# ATSAMA5D26 register map
Vendor: Microchip Technology; Series: SAMA5D2; File version: 0
Registers are 32-bit, read-write, reset 0x0 unless marked. A register's access mark holds for its fields unless they carry their own. Offsets are from the block's base; [hi:lo] are bit positions; 'fields as' and 'values as' point back to an identical list.

## PDMIC — Pulse Density Modulation Interface Controller
Base 0xF8018000
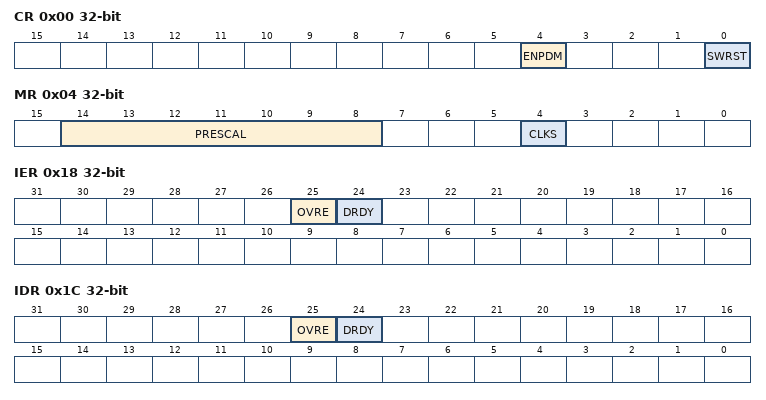
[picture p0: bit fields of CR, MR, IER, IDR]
0x00 CR — Control Register
  [4] ENPDM — Enable PDM
  [0] SWRST — Software Reset
0x04 MR — Mode Register
  [14:8] PRESCAL — Prescaler Rate Selection
  [4] CLKS — Clock Source Selection
0x14 CDR ro — Converted Data Register
  [31:0] DATA — Data Converted
0x18 IER wo — Interrupt Enable Register
  [25] OVRE — Overrun Error Interrupt Enable
  [24] DRDY — Data Ready Interrupt Enable
0x1C IDR wo — Interrupt Disable Register
  [25] OVRE — General Overrun Error Interrupt Disable
  [24] DRDY — Data Ready Interrupt Disable
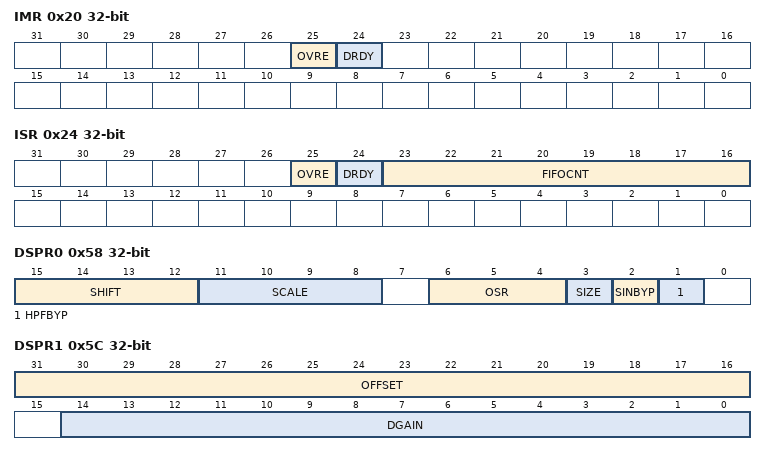
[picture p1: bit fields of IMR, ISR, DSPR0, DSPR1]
0x20 IMR ro — Interrupt Mask Register
  [25] OVRE — General Overrun Error Interrupt Mask
  [24] DRDY — Data Ready Interrupt Mask
0x24 ISR ro — Interrupt Status Register
  [25] OVRE — Overrun Error (cleared on read)
  [24] DRDY — Data Ready (cleared by reading PDMIC_CDR)
  [23:16] FIFOCNT — FIFO Count
0x58 DSPR0 — DSP Configuration Register 0
  [15:12] SHIFT — Data Shift
  [11:8] SCALE — Data Scale
  [6:4] OSR — Global Oversampling Ratio
    0=Global Oversampling ratio is 128 (SINC filter oversampling ratio is 64); 1=Global Oversampling ratio is 64 (SINC filter oversampling ratio is 32)
  [3] SIZE — Data Size
  [2] SINBYP — SINCC Filter Bypass
  [1] HPFBYP — High-Pass Filter Bypass
0x5C DSPR1 — DSP Configuration Register 1
  [31:16] OFFSET — Offset Correction
  [14:0] DGAIN — Gain Correction
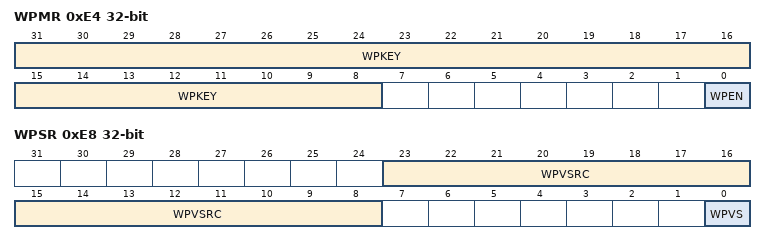
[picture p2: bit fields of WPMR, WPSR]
0xE4 WPMR — Write Protection Mode Register
  [31:8] WPKEY — Write Protection Key
    0x414443=PASSWD (Writing any other value in this field aborts the write operation of the WPEN bit.Always reads as 0.)
  [0] WPEN — Write Protection Enable
0xE8 WPSR ro — Write Protection Status Register
  [23:8] WPVSRC — Write Protection Violation Source
  [0] WPVS — Write Protection Violation Status

## PIT — Periodic Interval Timer
Base 0xF8048030
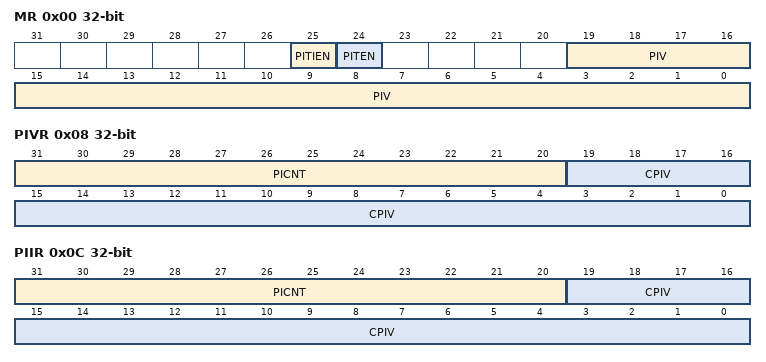
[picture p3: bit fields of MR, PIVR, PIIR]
0x00 MR — Mode Register
  [25] PITIEN — Periodic Interval Timer Interrupt Enable
  [24] PITEN — Period Interval Timer Enabled
  [19:0] PIV — Periodic Interval Value
0x04 SR ro — Status Register
  [0] PITS — Periodic Interval Timer Status
0x08 PIVR ro — Periodic Interval Value Register
  [31:20] PICNT — Periodic Interval Counter
  [19:0] CPIV — Current Periodic Interval Value
0x0C PIIR ro — Periodic Interval Image Register
  fields as PIVR

## RSTC — Reset Controller
Base 0xF8048000
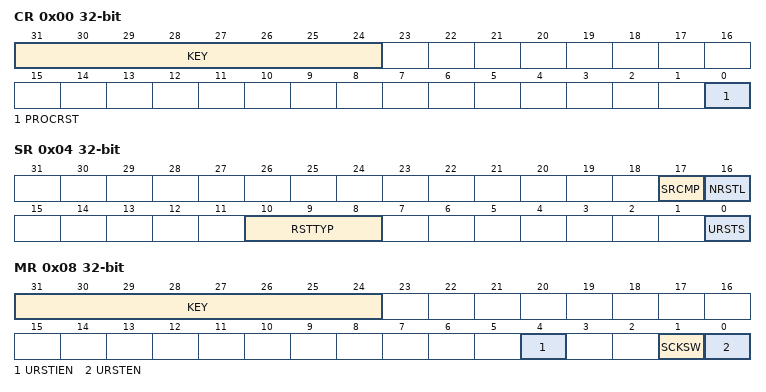
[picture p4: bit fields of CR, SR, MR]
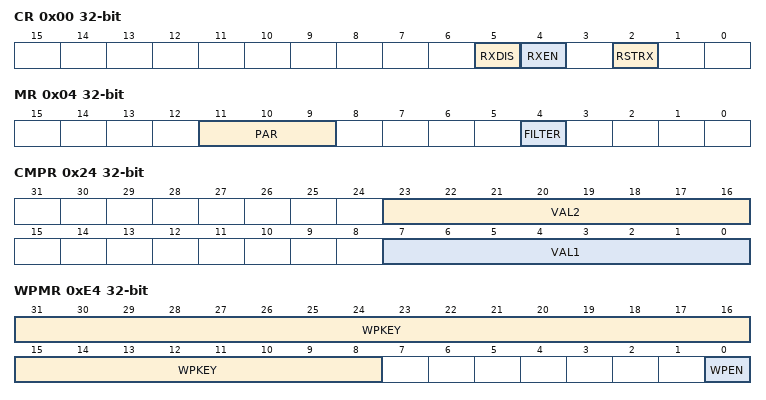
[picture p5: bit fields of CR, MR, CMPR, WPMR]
0x00 CR wo — Control Register
  [31:24] KEY — Write Access Password
    165=PASSWD (Writing any other value in this field aborts the write operation.Always reads as 0.)
  [0] PROCRST — Processor Reset
0x04 SR ro — Status Register
  [17] SRCMP — Software Reset Command in Progress
  [16] NRSTL — NRST Pin Level
  [10:8] RSTTYP — Reset Type
    0=GENERAL_RST (Both VDDCORE and VDDBU rising); 1=WKUP_RST (VDDCORE rising); 2=WDT_RST (Watchdog fault occurred); 3=SOFT_RST (Processor reset required by the software); 4=USER_RST (NRST pin detected low)
  [0] URSTS — User Reset Status
0x08 MR — Mode Register
  [31:24] KEY — Write Access Password
    values as CR.KEY
  [4] URSTIEN — User Reset Interrupt Enable
  [1] SCKSW — Slow Clock Switching
  [0] URSTEN — User Reset Enable

## RXLP — Low Power Asynchronous Receiver
Base 0xF8049000
0x00 CR wo — Control Register
  [5] RXDIS — Receiver Disable
  [4] RXEN — Receiver Enable
  [2] RSTRX — Reset Receiver
0x04 MR — Mode Register
  [11:9] PAR — Parity Type
    0=EVEN (Even Parity); 1=ODD (Odd Parity); 2=SPACE (Parity forced to 0); 3=MARK (Parity forced to 1); 4=NO (No parity)
  [4] FILTER — Receiver Digital Filter
    0=DISABLED (RXLP does not filter the receive line.); 1=ENABLED (RXLP filters the receive line using a three-sample filter (16x-bit clock) (2 over 3 majority).)
0x18 RHR ro — Receive Holding Register
  [7:0] RXCHR — Received Character
0x20 BRGR — Baud Rate Generator Register
  [1:0] CD — Clock Divisor
0x24 CMPR — Comparison Register
  [23:16] VAL2 — Second Comparison Value for Received Character
  [7:0] VAL1 — First Comparison Value for Received Character
0xE4 WPMR — Write Protection Mode Register
  [31:8] WPKEY — Write Protection Key
    0x52584C=PASSWD (Writing any other value in this field aborts the write operation.Always reads as 0.)
  [0] WPEN — Write Protection Enable
